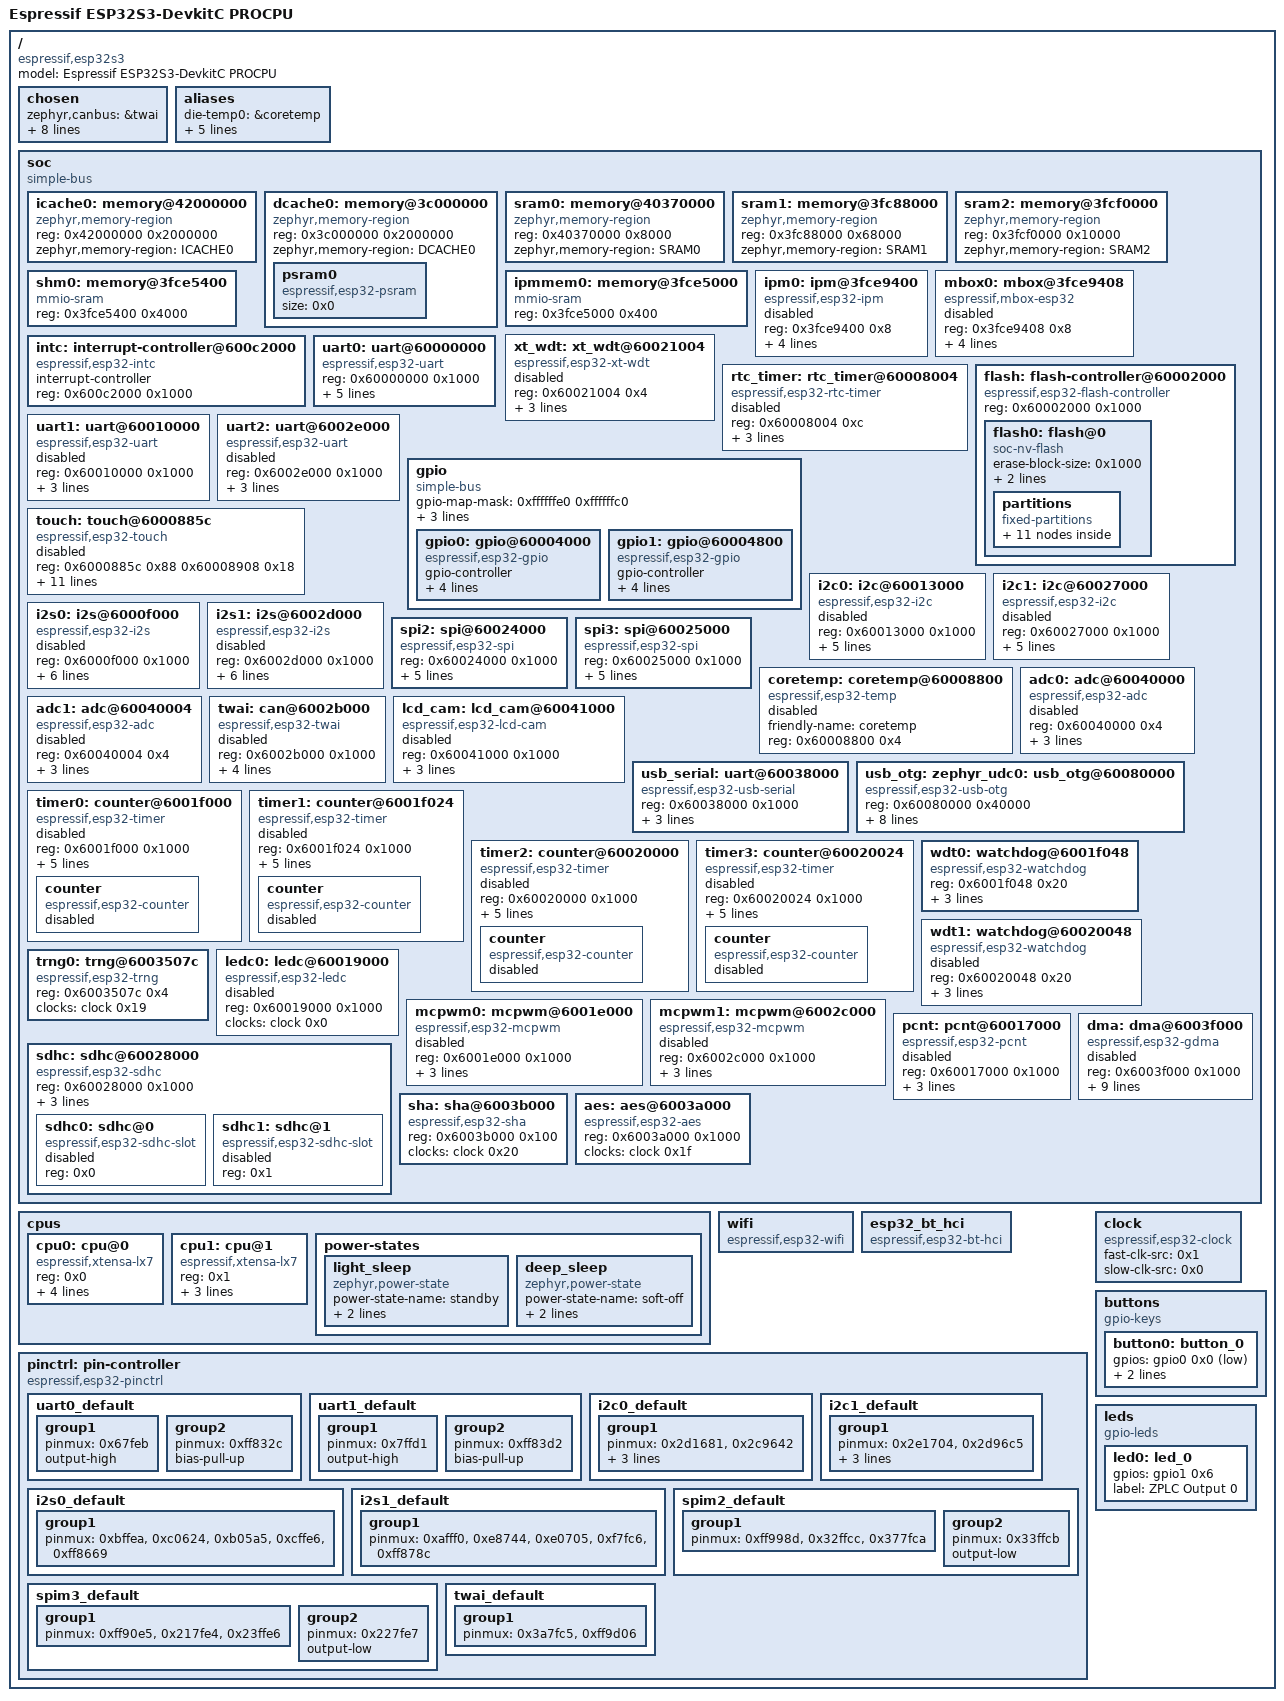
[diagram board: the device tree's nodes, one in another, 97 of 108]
/dts-v1/;

/* node '/' defined in zephyr/dts/common/skeleton.dtsi:9 */
/ {
	#address-cells = < 0x1 >;                   /* in zephyr/dts/common/skeleton.dtsi:10 */
	#size-cells = < 0x1 >;                      /* in zephyr/dts/common/skeleton.dtsi:11 */
	model = "Espressif ESP32S3-DevkitC PROCPU"; /* in zephyr/boards/espressif/esp32s3_devkitc/esp32s3_devkitc_procpu.dts:15 */
	compatible = "espressif,esp32s3";           /* in zephyr/boards/espressif/esp32s3_devkitc/esp32s3_devkitc_procpu.dts:16 */

	/* node '/chosen' defined in zephyr/dts/common/skeleton.dtsi:13 */
	chosen {
		zephyr,canbus = &twai;                    /* in zephyr/dts/xtensa/espressif/esp32s3/esp32s3_common.dtsi:22 */
		zephyr,entropy = &trng0;                  /* in zephyr/dts/xtensa/espressif/esp32s3/esp32s3_common.dtsi:23 */
		zephyr,flash-controller = &flash;         /* in zephyr/dts/xtensa/espressif/esp32s3/esp32s3_common.dtsi:24 */
		zephyr,sram = &sram1;                     /* in zephyr/boards/espressif/esp32s3_devkitc/esp32s3_devkitc_procpu.dts:24 */
		zephyr,flash = &flash0;                   /* in zephyr/boards/espressif/esp32s3_devkitc/esp32s3_devkitc_procpu.dts:27 */
		zephyr,code-partition = &slot0_partition; /* in zephyr/boards/espressif/esp32s3_devkitc/esp32s3_devkitc_procpu.dts:28 */
		zephyr,bt-hci = &esp32_bt_hci;            /* in zephyr/boards/espressif/esp32s3_devkitc/esp32s3_devkitc_procpu.dts:29 */
		zephyr,console = &usb_serial;             /* in ../Documents/Repos/ZPLC/firmware/app/boards/esp32s3_devkitc_esp32s3_procpu.overlay:27 */
		zephyr,shell-uart = &usb_serial;          /* in ../Documents/Repos/ZPLC/firmware/app/boards/esp32s3_devkitc_esp32s3_procpu.overlay:28 */
	};

	/* node '/aliases' defined in zephyr/dts/common/skeleton.dtsi:15 */
	aliases {
		die-temp0 = &coretemp; /* in zephyr/dts/xtensa/espressif/esp32s3/esp32s3_common.dtsi:18 */
		i2c-0 = &i2c0;         /* in zephyr/boards/espressif/esp32s3_devkitc/esp32s3_devkitc_procpu.dts:19 */
		watchdog0 = &wdt0;     /* in zephyr/boards/espressif/esp32s3_devkitc/esp32s3_devkitc_procpu.dts:20 */
		uart-0 = &uart0;       /* in zephyr/boards/espressif/esp32s3_devkitc/esp32s3_devkitc_procpu.dts:33 */
		sw0 = &button0;        /* in zephyr/boards/espressif/esp32s3_devkitc/esp32s3_devkitc_procpu.dts:34 */
		led0 = &led0;          /* in ../Documents/Repos/ZPLC/firmware/app/boards/esp32s3_devkitc_esp32s3_procpu.overlay:42 */
	};

	/* node '/soc' defined in zephyr/dts/xtensa/xtensa.dtsi:10 */
	soc {
		#address-cells = < 0x1 >;  /* in zephyr/dts/xtensa/espressif/esp32s3/esp32s3_common.dtsi:91 */
		#size-cells = < 0x1 >;     /* in zephyr/dts/xtensa/espressif/esp32s3/esp32s3_common.dtsi:92 */
		compatible = "simple-bus"; /* in zephyr/dts/xtensa/espressif/esp32s3/esp32s3_common.dtsi:93 */
		ranges;                    /* in zephyr/dts/xtensa/espressif/esp32s3/esp32s3_common.dtsi:94 */

		/* node '/soc/memory@42000000' defined in zephyr/dts/xtensa/espressif/esp32s3/esp32s3_common.dtsi:96 */
		icache0: memory@42000000 {
			compatible = "zephyr,memory-region"; /* in zephyr/dts/xtensa/espressif/esp32s3/esp32s3_common.dtsi:97 */
			reg = < 0x42000000 0x2000000 >;      /* in zephyr/dts/xtensa/espressif/esp32s3/esp32s3_common.dtsi:98 */
			zephyr,memory-region = "ICACHE0";    /* in zephyr/dts/xtensa/espressif/esp32s3/esp32s3_common.dtsi:99 */
		};

		/* node '/soc/memory@3c000000' defined in zephyr/dts/xtensa/espressif/esp32s3/esp32s3_common.dtsi:102 */
		dcache0: memory@3c000000 {
			compatible = "zephyr,memory-region"; /* in zephyr/dts/xtensa/espressif/esp32s3/esp32s3_common.dtsi:103 */
			reg = < 0x3c000000 0x2000000 >;      /* in zephyr/dts/xtensa/espressif/esp32s3/esp32s3_common.dtsi:104 */
			zephyr,memory-region = "DCACHE0";    /* in zephyr/dts/xtensa/espressif/esp32s3/esp32s3_common.dtsi:105 */

			/* node '/soc/memory@3c000000/psram0' defined in zephyr/dts/xtensa/espressif/esp32s3/esp32s3_common.dtsi:107 */
			psram0: psram0 {
				compatible = "espressif,esp32-psram"; /* in zephyr/dts/xtensa/espressif/esp32s3/esp32s3_common.dtsi:108 */
				size = < 0x0 >;                       /* in zephyr/dts/xtensa/espressif/esp32s3/esp32s3_common.dtsi:109 */
			};
		};

		/* node '/soc/memory@40370000' defined in zephyr/dts/xtensa/espressif/esp32s3/esp32s3_common.dtsi:113 */
		sram0: memory@40370000 {
			compatible = "zephyr,memory-region",
			             "mmio-sram";            /* in zephyr/dts/xtensa/espressif/esp32s3/esp32s3_common.dtsi:114 */
			reg = < 0x40370000 0x8000 >;         /* in zephyr/dts/xtensa/espressif/esp32s3/esp32s3_common.dtsi:115 */
			zephyr,memory-region = "SRAM0";      /* in zephyr/dts/xtensa/espressif/esp32s3/esp32s3_common.dtsi:116 */
		};

		/* node '/soc/memory@3fc88000' defined in zephyr/dts/xtensa/espressif/esp32s3/esp32s3_common.dtsi:119 */
		sram1: memory@3fc88000 {
			compatible = "zephyr,memory-region",
			             "mmio-sram";            /* in zephyr/dts/xtensa/espressif/esp32s3/esp32s3_common.dtsi:120 */
			reg = < 0x3fc88000 0x68000 >;        /* in zephyr/dts/xtensa/espressif/esp32s3/esp32s3_common.dtsi:121 */
			zephyr,memory-region = "SRAM1";      /* in zephyr/dts/xtensa/espressif/esp32s3/esp32s3_common.dtsi:122 */
		};

		/* node '/soc/memory@3fcf0000' defined in zephyr/dts/xtensa/espressif/esp32s3/esp32s3_common.dtsi:125 */
		sram2: memory@3fcf0000 {
			compatible = "zephyr,memory-region",
			             "mmio-sram";            /* in zephyr/dts/xtensa/espressif/esp32s3/esp32s3_common.dtsi:126 */
			reg = < 0x3fcf0000 0x10000 >;        /* in zephyr/dts/xtensa/espressif/esp32s3/esp32s3_common.dtsi:127 */
			zephyr,memory-region = "SRAM2";      /* in zephyr/dts/xtensa/espressif/esp32s3/esp32s3_common.dtsi:128 */
		};

		/* node '/soc/memory@3fce5000' defined in zephyr/dts/xtensa/espressif/esp32s3/esp32s3_common.dtsi:131 */
		ipmmem0: memory@3fce5000 {
			compatible = "mmio-sram";   /* in zephyr/dts/xtensa/espressif/esp32s3/esp32s3_common.dtsi:132 */
			reg = < 0x3fce5000 0x400 >; /* in zephyr/dts/xtensa/espressif/esp32s3/esp32s3_common.dtsi:133 */
			phandle = < 0x1 >;          /* in zephyr/dts/xtensa/espressif/esp32s3/esp32s3_common.dtsi:145 */
		};

		/* node '/soc/memory@3fce5400' defined in zephyr/dts/xtensa/espressif/esp32s3/esp32s3_common.dtsi:136 */
		shm0: memory@3fce5400 {
			compatible = "mmio-sram";    /* in zephyr/dts/xtensa/espressif/esp32s3/esp32s3_common.dtsi:137 */
			reg = < 0x3fce5400 0x4000 >; /* in zephyr/dts/xtensa/espressif/esp32s3/esp32s3_common.dtsi:138 */
		};

		/* node '/soc/ipm@3fce9400' defined in zephyr/dts/xtensa/espressif/esp32s3/esp32s3_common.dtsi:141 */
		ipm0: ipm@3fce9400 {
			compatible = "espressif,esp32-ipm"; /* in zephyr/dts/xtensa/espressif/esp32s3/esp32s3_common.dtsi:142 */
			reg = < 0x3fce9400 0x8 >;           /* in zephyr/dts/xtensa/espressif/esp32s3/esp32s3_common.dtsi:143 */
			status = "disabled";                /* in zephyr/dts/xtensa/espressif/esp32s3/esp32s3_common.dtsi:144 */
			shared-memory = < &ipmmem0 >;       /* in zephyr/dts/xtensa/espressif/esp32s3/esp32s3_common.dtsi:145 */
			shared-memory-size = < 0x400 >;     /* in zephyr/dts/xtensa/espressif/esp32s3/esp32s3_common.dtsi:146 */
			interrupts = < 0x4f 0x0 0x0 >,
			             < 0x50 0x0 0x0 >;      /* in zephyr/dts/xtensa/espressif/esp32s3/esp32s3_common.dtsi:147 */
			interrupt-parent = < &intc >;       /* in zephyr/dts/xtensa/espressif/esp32s3/esp32s3_common.dtsi:149 */
		};

		/* node '/soc/mbox@3fce9408' defined in zephyr/dts/xtensa/espressif/esp32s3/esp32s3_common.dtsi:152 */
		mbox0: mbox@3fce9408 {
			compatible = "espressif,mbox-esp32"; /* in zephyr/dts/xtensa/espressif/esp32s3/esp32s3_common.dtsi:153 */
			reg = < 0x3fce9408 0x8 >;            /* in zephyr/dts/xtensa/espressif/esp32s3/esp32s3_common.dtsi:154 */
			status = "disabled";                 /* in zephyr/dts/xtensa/espressif/esp32s3/esp32s3_common.dtsi:155 */
			shared-memory = < &ipmmem0 >;        /* in zephyr/dts/xtensa/espressif/esp32s3/esp32s3_common.dtsi:156 */
			shared-memory-size = < 0x400 >;      /* in zephyr/dts/xtensa/espressif/esp32s3/esp32s3_common.dtsi:157 */
			interrupts = < 0x4f 0x0 0x0 >,
			             < 0x50 0x0 0x0 >;       /* in zephyr/dts/xtensa/espressif/esp32s3/esp32s3_common.dtsi:158 */
			interrupt-parent = < &intc >;        /* in zephyr/dts/xtensa/espressif/esp32s3/esp32s3_common.dtsi:160 */
			#mbox-cells = < 0x1 >;               /* in zephyr/dts/xtensa/espressif/esp32s3/esp32s3_common.dtsi:161 */
		};

		/* node '/soc/interrupt-controller@600c2000' defined in zephyr/dts/xtensa/espressif/esp32s3/esp32s3_common.dtsi:164 */
		intc: interrupt-controller@600c2000 {
			#interrupt-cells = < 0x3 >;          /* in zephyr/dts/xtensa/espressif/esp32s3/esp32s3_common.dtsi:165 */
			#address-cells = < 0x0 >;            /* in zephyr/dts/xtensa/espressif/esp32s3/esp32s3_common.dtsi:166 */
			compatible = "espressif,esp32-intc"; /* in zephyr/dts/xtensa/espressif/esp32s3/esp32s3_common.dtsi:167 */
			interrupt-controller;                /* in zephyr/dts/xtensa/espressif/esp32s3/esp32s3_common.dtsi:168 */
			reg = < 0x600c2000 0x1000 >;         /* in zephyr/dts/xtensa/espressif/esp32s3/esp32s3_common.dtsi:169 */
			status = "okay";                     /* in zephyr/dts/xtensa/espressif/esp32s3/esp32s3_common.dtsi:170 */
			phandle = < 0x2 >;                   /* in zephyr/dts/xtensa/espressif/esp32s3/esp32s3_common.dtsi:149 */
		};

		/* node '/soc/xt_wdt@60021004' defined in zephyr/dts/xtensa/espressif/esp32s3/esp32s3_common.dtsi:173 */
		xt_wdt: xt_wdt@60021004 {
			compatible = "espressif,esp32-xt-wdt"; /* in zephyr/dts/xtensa/espressif/esp32s3/esp32s3_common.dtsi:174 */
			reg = < 0x60021004 0x4 >;              /* in zephyr/dts/xtensa/espressif/esp32s3/esp32s3_common.dtsi:175 */
			clocks = < &clock 0x28 >;              /* in zephyr/dts/xtensa/espressif/esp32s3/esp32s3_common.dtsi:176 */
			interrupts = < 0x27 0x0 0x0 >;         /* in zephyr/dts/xtensa/espressif/esp32s3/esp32s3_common.dtsi:177 */
			interrupt-parent = < &intc >;          /* in zephyr/dts/xtensa/espressif/esp32s3/esp32s3_common.dtsi:178 */
			status = "disabled";                   /* in zephyr/dts/xtensa/espressif/esp32s3/esp32s3_common.dtsi:179 */
		};

		/* node '/soc/rtc_timer@60008004' defined in zephyr/dts/xtensa/espressif/esp32s3/esp32s3_common.dtsi:182 */
		rtc_timer: rtc_timer@60008004 {
			reg = < 0x60008004 0xc >;                 /* in zephyr/dts/xtensa/espressif/esp32s3/esp32s3_common.dtsi:183 */
			compatible = "espressif,esp32-rtc-timer"; /* in zephyr/dts/xtensa/espressif/esp32s3/esp32s3_common.dtsi:184 */
			clocks = < &clock 0x28 >;                 /* in zephyr/dts/xtensa/espressif/esp32s3/esp32s3_common.dtsi:185 */
			interrupts = < 0x27 0x0 0x0 >;            /* in zephyr/dts/xtensa/espressif/esp32s3/esp32s3_common.dtsi:186 */
			interrupt-parent = < &intc >;             /* in zephyr/dts/xtensa/espressif/esp32s3/esp32s3_common.dtsi:187 */
			status = "disabled";                      /* in zephyr/dts/xtensa/espressif/esp32s3/esp32s3_common.dtsi:188 */
		};

		/* node '/soc/flash-controller@60002000' defined in zephyr/dts/xtensa/espressif/esp32s3/esp32s3_common.dtsi:191 */
		flash: flash-controller@60002000 {
			compatible = "espressif,esp32-flash-controller"; /* in zephyr/dts/xtensa/espressif/esp32s3/esp32s3_common.dtsi:192 */
			reg = < 0x60002000 0x1000 >;                     /* in zephyr/dts/xtensa/espressif/esp32s3/esp32s3_common.dtsi:193 */
			#address-cells = < 0x1 >;                        /* in zephyr/dts/xtensa/espressif/esp32s3/esp32s3_common.dtsi:194 */
			#size-cells = < 0x1 >;                           /* in zephyr/dts/xtensa/espressif/esp32s3/esp32s3_common.dtsi:195 */

			/* node '/soc/flash-controller@60002000/flash@0' defined in zephyr/dts/xtensa/espressif/esp32s3/esp32s3_common.dtsi:197 */
			flash0: flash@0 {
				compatible = "soc-nv-flash";   /* in zephyr/dts/xtensa/espressif/esp32s3/esp32s3_common.dtsi:198 */
				erase-block-size = < 0x1000 >; /* in zephyr/dts/xtensa/espressif/esp32s3/esp32s3_common.dtsi:199 */
				write-block-size = < 0x4 >;    /* in zephyr/dts/xtensa/espressif/esp32s3/esp32s3_common.dtsi:200 */
				reg = < 0x0 0x800000 >;        /* in zephyr/dts/xtensa/espressif/esp32s3/esp32s3_wroom_n8.dtsi:11 */

				/* node '/soc/flash-controller@60002000/flash@0/partitions' defined in zephyr/dts/vendor/espressif/partitions_0x0_amp_4M.dtsi:8 */
				partitions {
					compatible = "fixed-partitions"; /* in zephyr/dts/vendor/espressif/partitions_0x0_amp_4M.dtsi:9 */
					#address-cells = < 0x1 >;        /* in zephyr/dts/vendor/espressif/partitions_0x0_amp_4M.dtsi:10 */
					#size-cells = < 0x1 >;           /* in zephyr/dts/vendor/espressif/partitions_0x0_amp_4M.dtsi:11 */

					/* node '/soc/flash-controller@60002000/flash@0/partitions/partition@0' defined in zephyr/dts/vendor/espressif/partitions_0x0_amp_4M.dtsi:13 */
					boot_partition: partition@0 {
						label = "mcuboot";     /* in zephyr/dts/vendor/espressif/partitions_0x0_amp_4M.dtsi:14 */
						reg = < 0x0 0x10000 >; /* in zephyr/dts/vendor/espressif/partitions_0x0_amp_4M.dtsi:15 */
					};

					/* node '/soc/flash-controller@60002000/flash@0/partitions/partition@10000' defined in zephyr/dts/vendor/espressif/partitions_0x0_amp_4M.dtsi:18 */
					sys_partition: partition@10000 {
						label = "sys";             /* in zephyr/dts/vendor/espressif/partitions_0x0_amp_4M.dtsi:19 */
						reg = < 0x10000 0x10000 >; /* in zephyr/dts/vendor/espressif/partitions_0x0_amp_4M.dtsi:20 */
					};

					/* node '/soc/flash-controller@60002000/flash@0/partitions/partition@20000' defined in zephyr/dts/vendor/espressif/partitions_0x0_amp_4M.dtsi:23 */
					slot0_partition: partition@20000 {
						label = "image-0";          /* in zephyr/dts/vendor/espressif/partitions_0x0_amp_4M.dtsi:24 */
						reg = < 0x20000 0x150000 >; /* in zephyr/dts/vendor/espressif/partitions_0x0_amp_4M.dtsi:25 */
					};

					/* node '/soc/flash-controller@60002000/flash@0/partitions/partition@170000' defined in zephyr/dts/vendor/espressif/partitions_0x0_amp_4M.dtsi:28 */
					slot1_partition: partition@170000 {
						label = "image-1";           /* in zephyr/dts/vendor/espressif/partitions_0x0_amp_4M.dtsi:29 */
						reg = < 0x170000 0x150000 >; /* in zephyr/dts/vendor/espressif/partitions_0x0_amp_4M.dtsi:30 */
					};

					/* node '/soc/flash-controller@60002000/flash@0/partitions/partition@2c0000' defined in zephyr/dts/vendor/espressif/partitions_0x0_amp_4M.dtsi:33 */
					slot0_appcpu_partition: partition@2c0000 {
						label = "image-0-appcpu";   /* in zephyr/dts/vendor/espressif/partitions_0x0_amp_4M.dtsi:34 */
						reg = < 0x2c0000 0x70000 >; /* in zephyr/dts/vendor/espressif/partitions_0x0_amp_4M.dtsi:35 */
					};

					/* node '/soc/flash-controller@60002000/flash@0/partitions/partition@330000' defined in zephyr/dts/vendor/espressif/partitions_0x0_amp_4M.dtsi:38 */
					slot1_appcpu_partition: partition@330000 {
						label = "image-1-appcpu";   /* in zephyr/dts/vendor/espressif/partitions_0x0_amp_4M.dtsi:39 */
						reg = < 0x330000 0x70000 >; /* in zephyr/dts/vendor/espressif/partitions_0x0_amp_4M.dtsi:40 */
					};

					/* node '/soc/flash-controller@60002000/flash@0/partitions/partition@3a0000' defined in zephyr/dts/vendor/espressif/partitions_0x0_amp_4M.dtsi:43 */
					slot0_lpcore_partition: partition@3a0000 {
						label = "image-0-lpcore";  /* in zephyr/dts/vendor/espressif/partitions_0x0_amp_4M.dtsi:44 */
						reg = < 0x3a0000 0x8000 >; /* in zephyr/dts/vendor/espressif/partitions_0x0_amp_4M.dtsi:45 */
					};

					/* node '/soc/flash-controller@60002000/flash@0/partitions/partition@3a8000' defined in zephyr/dts/vendor/espressif/partitions_0x0_amp_4M.dtsi:48 */
					slot1_lpcore_partition: partition@3a8000 {
						label = "image-1-lpcore";  /* in zephyr/dts/vendor/espressif/partitions_0x0_amp_4M.dtsi:49 */
						reg = < 0x3a8000 0x8000 >; /* in zephyr/dts/vendor/espressif/partitions_0x0_amp_4M.dtsi:50 */
					};

					/* node '/soc/flash-controller@60002000/flash@0/partitions/partition@3b0000' defined in zephyr/dts/vendor/espressif/partitions_0x0_amp_4M.dtsi:53 */
					storage_partition: partition@3b0000 {
						label = "storage";          /* in zephyr/dts/vendor/espressif/partitions_0x0_amp_4M.dtsi:54 */
						reg = < 0x3b0000 0x30000 >; /* in zephyr/dts/vendor/espressif/partitions_0x0_amp_4M.dtsi:55 */
					};

					/* node '/soc/flash-controller@60002000/flash@0/partitions/partition@3e0000' defined in zephyr/dts/vendor/espressif/partitions_0x0_amp_4M.dtsi:58 */
					scratch_partition: partition@3e0000 {
						label = "image-scratch";    /* in zephyr/dts/vendor/espressif/partitions_0x0_amp_4M.dtsi:59 */
						reg = < 0x3e0000 0x1f000 >; /* in zephyr/dts/vendor/espressif/partitions_0x0_amp_4M.dtsi:60 */
					};

					/* node '/soc/flash-controller@60002000/flash@0/partitions/partition@3ff000' defined in zephyr/dts/vendor/espressif/partitions_0x0_amp_4M.dtsi:63 */
					coredump_partition: partition@3ff000 {
						label = "coredump";        /* in zephyr/dts/vendor/espressif/partitions_0x0_amp_4M.dtsi:64 */
						reg = < 0x3ff000 0x1000 >; /* in zephyr/dts/vendor/espressif/partitions_0x0_amp_4M.dtsi:65 */
					};
				};
			};
		};

		/* node '/soc/uart@60000000' defined in zephyr/dts/xtensa/espressif/esp32s3/esp32s3_common.dtsi:205 */
		uart0: uart@60000000 {
			compatible = "espressif,esp32-uart"; /* in zephyr/dts/xtensa/espressif/esp32s3/esp32s3_common.dtsi:206 */
			reg = < 0x60000000 0x1000 >;         /* in zephyr/dts/xtensa/espressif/esp32s3/esp32s3_common.dtsi:207 */
			interrupts = < 0x1b 0x0 0x0 >;       /* in zephyr/dts/xtensa/espressif/esp32s3/esp32s3_common.dtsi:208 */
			interrupt-parent = < &intc >;        /* in zephyr/dts/xtensa/espressif/esp32s3/esp32s3_common.dtsi:209 */
			clocks = < &clock 0x1 >;             /* in zephyr/dts/xtensa/espressif/esp32s3/esp32s3_common.dtsi:210 */
			status = "okay";                     /* in zephyr/boards/espressif/esp32s3_devkitc/esp32s3_devkitc_procpu.dts:53 */
			current-speed = < 0x1c200 >;         /* in zephyr/boards/espressif/esp32s3_devkitc/esp32s3_devkitc_procpu.dts:54 */
			pinctrl-0 = < &uart0_default >;      /* in zephyr/boards/espressif/esp32s3_devkitc/esp32s3_devkitc_procpu.dts:55 */
			pinctrl-names = "default";           /* in zephyr/boards/espressif/esp32s3_devkitc/esp32s3_devkitc_procpu.dts:56 */
		};

		/* node '/soc/uart@60010000' defined in zephyr/dts/xtensa/espressif/esp32s3/esp32s3_common.dtsi:214 */
		uart1: uart@60010000 {
			compatible = "espressif,esp32-uart"; /* in zephyr/dts/xtensa/espressif/esp32s3/esp32s3_common.dtsi:215 */
			reg = < 0x60010000 0x1000 >;         /* in zephyr/dts/xtensa/espressif/esp32s3/esp32s3_common.dtsi:216 */
			interrupts = < 0x1c 0x0 0x0 >;       /* in zephyr/dts/xtensa/espressif/esp32s3/esp32s3_common.dtsi:217 */
			interrupt-parent = < &intc >;        /* in zephyr/dts/xtensa/espressif/esp32s3/esp32s3_common.dtsi:218 */
			clocks = < &clock 0x2 >;             /* in zephyr/dts/xtensa/espressif/esp32s3/esp32s3_common.dtsi:219 */
			status = "disabled";                 /* in zephyr/dts/xtensa/espressif/esp32s3/esp32s3_common.dtsi:220 */
		};

		/* node '/soc/uart@6002e000' defined in zephyr/dts/xtensa/espressif/esp32s3/esp32s3_common.dtsi:223 */
		uart2: uart@6002e000 {
			compatible = "espressif,esp32-uart"; /* in zephyr/dts/xtensa/espressif/esp32s3/esp32s3_common.dtsi:224 */
			reg = < 0x6002e000 0x1000 >;         /* in zephyr/dts/xtensa/espressif/esp32s3/esp32s3_common.dtsi:225 */
			interrupts = < 0x1d 0x0 0x0 >;       /* in zephyr/dts/xtensa/espressif/esp32s3/esp32s3_common.dtsi:226 */
			interrupt-parent = < &intc >;        /* in zephyr/dts/xtensa/espressif/esp32s3/esp32s3_common.dtsi:227 */
			clocks = < &clock 0x3 >;             /* in zephyr/dts/xtensa/espressif/esp32s3/esp32s3_common.dtsi:228 */
			status = "disabled";                 /* in zephyr/dts/xtensa/espressif/esp32s3/esp32s3_common.dtsi:229 */
		};

		/* node '/soc/gpio' defined in zephyr/dts/xtensa/espressif/esp32s3/esp32s3_common.dtsi:232 */
		gpio: gpio {
			compatible = "simple-bus";                                     /* in zephyr/dts/xtensa/espressif/esp32s3/esp32s3_common.dtsi:233 */
			gpio-map-mask = < 0xffffffe0 0xffffffc0 >;                     /* in zephyr/dts/xtensa/espressif/esp32s3/esp32s3_common.dtsi:234 */
			gpio-map-pass-thru = < 0x1f 0x3f >;                            /* in zephyr/dts/xtensa/espressif/esp32s3/esp32s3_common.dtsi:235 */
			gpio-map = < 0x0 0x0 &gpio0 0x0 0x0 0x20 0x0 &gpio1 0x0 0x0 >; /* in zephyr/dts/xtensa/espressif/esp32s3/esp32s3_common.dtsi:236 */
			#gpio-cells = < 0x2 >;                                         /* in zephyr/dts/xtensa/espressif/esp32s3/esp32s3_common.dtsi:238 */
			#address-cells = < 0x1 >;                                      /* in zephyr/dts/xtensa/espressif/esp32s3/esp32s3_common.dtsi:239 */
			#size-cells = < 0x1 >;                                         /* in zephyr/dts/xtensa/espressif/esp32s3/esp32s3_common.dtsi:240 */
			ranges;                                                        /* in zephyr/dts/xtensa/espressif/esp32s3/esp32s3_common.dtsi:241 */

			/* node '/soc/gpio/gpio@60004000' defined in zephyr/dts/xtensa/espressif/esp32s3/esp32s3_common.dtsi:243 */
			gpio0: gpio@60004000 {
				compatible = "espressif,esp32-gpio"; /* in zephyr/dts/xtensa/espressif/esp32s3/esp32s3_common.dtsi:244 */
				gpio-controller;                     /* in zephyr/dts/xtensa/espressif/esp32s3/esp32s3_common.dtsi:245 */
				#gpio-cells = < 0x2 >;               /* in zephyr/dts/xtensa/espressif/esp32s3/esp32s3_common.dtsi:246 */
				reg = < 0x60004000 0x800 >;          /* in zephyr/dts/xtensa/espressif/esp32s3/esp32s3_common.dtsi:247 */
				interrupts = < 0x10 0x0 0x0 >;       /* in zephyr/dts/xtensa/espressif/esp32s3/esp32s3_common.dtsi:248 */
				interrupt-parent = < &intc >;        /* in zephyr/dts/xtensa/espressif/esp32s3/esp32s3_common.dtsi:249 */
				ngpios = < 0x20 >;                   /* in zephyr/dts/xtensa/espressif/esp32s3/esp32s3_common.dtsi:255 */
				status = "okay";                     /* in zephyr/boards/espressif/esp32s3_devkitc/esp32s3_devkitc_procpu.dts:60 */
				phandle = < 0x5 >;                   /* in zephyr/dts/xtensa/espressif/esp32s3/esp32s3_common.dtsi:236 */
			};

			/* node '/soc/gpio/gpio@60004800' defined in zephyr/dts/xtensa/espressif/esp32s3/esp32s3_common.dtsi:258 */
			gpio1: gpio@60004800 {
				compatible = "espressif,esp32-gpio"; /* in zephyr/dts/xtensa/espressif/esp32s3/esp32s3_common.dtsi:259 */
				gpio-controller;                     /* in zephyr/dts/xtensa/espressif/esp32s3/esp32s3_common.dtsi:260 */
				#gpio-cells = < 0x2 >;               /* in zephyr/dts/xtensa/espressif/esp32s3/esp32s3_common.dtsi:261 */
				reg = < 0x60004800 0x800 >;          /* in zephyr/dts/xtensa/espressif/esp32s3/esp32s3_common.dtsi:262 */
				interrupts = < 0x10 0x0 0x0 >;       /* in zephyr/dts/xtensa/espressif/esp32s3/esp32s3_common.dtsi:263 */
				interrupt-parent = < &intc >;        /* in zephyr/dts/xtensa/espressif/esp32s3/esp32s3_common.dtsi:264 */
				ngpios = < 0x16 >;                   /* in zephyr/dts/xtensa/espressif/esp32s3/esp32s3_common.dtsi:265 */
				status = "okay";                     /* in zephyr/boards/espressif/esp32s3_devkitc/esp32s3_devkitc_procpu.dts:64 */
				phandle = < 0x6 >;                   /* in zephyr/dts/xtensa/espressif/esp32s3/esp32s3_common.dtsi:236 */
			};
		};

		/* node '/soc/touch@6000885c' defined in zephyr/dts/xtensa/espressif/esp32s3/esp32s3_common.dtsi:269 */
		touch: touch@6000885c {
			compatible = "espressif,esp32-touch";      /* in zephyr/dts/xtensa/espressif/esp32s3/esp32s3_common.dtsi:270 */
			reg = < 0x6000885c 0x88 0x60008908 0x18 >; /* in zephyr/dts/xtensa/espressif/esp32s3/esp32s3_common.dtsi:271 */
			interrupts = < 0x27 0x0 0x0 >;             /* in zephyr/dts/xtensa/espressif/esp32s3/esp32s3_common.dtsi:272 */
			interrupt-parent = < &intc >;              /* in zephyr/dts/xtensa/espressif/esp32s3/esp32s3_common.dtsi:273 */
			status = "disabled";                       /* in zephyr/dts/xtensa/espressif/esp32s3/esp32s3_common.dtsi:274 */
			debounce-interval-ms = < 0x1e >;           /* in zephyr/boards/espressif/esp32s3_devkitc/esp32s3_devkitc_procpu.dts:68 */
			href-microvolt = < 0x2932e0 >;             /* in zephyr/boards/espressif/esp32s3_devkitc/esp32s3_devkitc_procpu.dts:69 */
			lref-microvolt = < 0x7a120 >;              /* in zephyr/boards/espressif/esp32s3_devkitc/esp32s3_devkitc_procpu.dts:70 */
			href-atten-microvolt = < 0xf4240 >;        /* in zephyr/boards/espressif/esp32s3_devkitc/esp32s3_devkitc_procpu.dts:71 */
			filter-mode = < 0x2 >;                     /* in zephyr/boards/espressif/esp32s3_devkitc/esp32s3_devkitc_procpu.dts:72 */
			filter-debounce-cnt = < 0x1 >;             /* in zephyr/boards/espressif/esp32s3_devkitc/esp32s3_devkitc_procpu.dts:73 */
			filter-noise-thr = < 0x0 >;                /* in zephyr/boards/espressif/esp32s3_devkitc/esp32s3_devkitc_procpu.dts:74 */
			filter-jitter-step = < 0x4 >;              /* in zephyr/boards/espressif/esp32s3_devkitc/esp32s3_devkitc_procpu.dts:75 */
			filter-smooth-level = < 0x1 >;             /* in zephyr/boards/espressif/esp32s3_devkitc/esp32s3_devkitc_procpu.dts:76 */
		};

		/* node '/soc/i2c@60013000' defined in zephyr/dts/xtensa/espressif/esp32s3/esp32s3_common.dtsi:277 */
		i2c0: i2c@60013000 {
			compatible = "espressif,esp32-i2c"; /* in zephyr/dts/xtensa/espressif/esp32s3/esp32s3_common.dtsi:278 */
			#address-cells = < 0x1 >;           /* in zephyr/dts/xtensa/espressif/esp32s3/esp32s3_common.dtsi:279 */
			#size-cells = < 0x0 >;              /* in zephyr/dts/xtensa/espressif/esp32s3/esp32s3_common.dtsi:280 */
			reg = < 0x60013000 0x1000 >;        /* in zephyr/dts/xtensa/espressif/esp32s3/esp32s3_common.dtsi:281 */
			interrupts = < 0x2a 0x0 0x0 >;      /* in zephyr/dts/xtensa/espressif/esp32s3/esp32s3_common.dtsi:282 */
			interrupt-parent = < &intc >;       /* in zephyr/dts/xtensa/espressif/esp32s3/esp32s3_common.dtsi:283 */
			clocks = < &clock 0x5 >;            /* in zephyr/dts/xtensa/espressif/esp32s3/esp32s3_common.dtsi:284 */
			status = "disabled";                /* in zephyr/dts/xtensa/espressif/esp32s3/esp32s3_common.dtsi:285 */
			clock-frequency = < 0x186a0 >;      /* in zephyr/boards/espressif/esp32s3_devkitc/esp32s3_devkitc_procpu.dts:80 */
			pinctrl-0 = < &i2c0_default >;      /* in zephyr/boards/espressif/esp32s3_devkitc/esp32s3_devkitc_procpu.dts:81 */
			pinctrl-names = "default";          /* in zephyr/boards/espressif/esp32s3_devkitc/esp32s3_devkitc_procpu.dts:82 */
		};

		/* node '/soc/i2c@60027000' defined in zephyr/dts/xtensa/espressif/esp32s3/esp32s3_common.dtsi:288 */
		i2c1: i2c@60027000 {
			compatible = "espressif,esp32-i2c"; /* in zephyr/dts/xtensa/espressif/esp32s3/esp32s3_common.dtsi:289 */
			#address-cells = < 0x1 >;           /* in zephyr/dts/xtensa/espressif/esp32s3/esp32s3_common.dtsi:290 */
			#size-cells = < 0x0 >;              /* in zephyr/dts/xtensa/espressif/esp32s3/esp32s3_common.dtsi:291 */
			reg = < 0x60027000 0x1000 >;        /* in zephyr/dts/xtensa/espressif/esp32s3/esp32s3_common.dtsi:292 */
			interrupts = < 0x2b 0x0 0x0 >;      /* in zephyr/dts/xtensa/espressif/esp32s3/esp32s3_common.dtsi:293 */
			interrupt-parent = < &intc >;       /* in zephyr/dts/xtensa/espressif/esp32s3/esp32s3_common.dtsi:294 */
			clocks = < &clock 0x6 >;            /* in zephyr/dts/xtensa/espressif/esp32s3/esp32s3_common.dtsi:295 */
			status = "disabled";                /* in zephyr/dts/xtensa/espressif/esp32s3/esp32s3_common.dtsi:296 */
			clock-frequency = < 0x186a0 >;      /* in zephyr/boards/espressif/esp32s3_devkitc/esp32s3_devkitc_procpu.dts:86 */
			pinctrl-0 = < &i2c1_default >;      /* in zephyr/boards/espressif/esp32s3_devkitc/esp32s3_devkitc_procpu.dts:87 */
			pinctrl-names = "default";          /* in zephyr/boards/espressif/esp32s3_devkitc/esp32s3_devkitc_procpu.dts:88 */
		};

		/* node '/soc/i2s@6000f000' defined in zephyr/dts/xtensa/espressif/esp32s3/esp32s3_common.dtsi:299 */
		i2s0: i2s@6000f000 {
			compatible = "espressif,esp32-i2s"; /* in zephyr/dts/xtensa/espressif/esp32s3/esp32s3_common.dtsi:300 */
			#address-cells = < 0x1 >;           /* in zephyr/dts/xtensa/espressif/esp32s3/esp32s3_common.dtsi:301 */
			#size-cells = < 0x0 >;              /* in zephyr/dts/xtensa/espressif/esp32s3/esp32s3_common.dtsi:302 */
			reg = < 0x6000f000 0x1000 >;        /* in zephyr/dts/xtensa/espressif/esp32s3/esp32s3_common.dtsi:303 */
			interrupts = < 0x19 0x0 0x0 >;      /* in zephyr/dts/xtensa/espressif/esp32s3/esp32s3_common.dtsi:304 */
			interrupt-parent = < &intc >;       /* in zephyr/dts/xtensa/espressif/esp32s3/esp32s3_common.dtsi:305 */
			clocks = < &clock 0x7 >;            /* in zephyr/dts/xtensa/espressif/esp32s3/esp32s3_common.dtsi:306 */
			dmas = < &dma 0x2 >,
			       < &dma 0x3 >;                /* in zephyr/dts/xtensa/espressif/esp32s3/esp32s3_common.dtsi:307 */
			dma-names = "rx",
			            "tx";                   /* in zephyr/dts/xtensa/espressif/esp32s3/esp32s3_common.dtsi:308 */
			unit = < 0x0 >;                     /* in zephyr/dts/xtensa/espressif/esp32s3/esp32s3_common.dtsi:309 */
			status = "disabled";                /* in zephyr/dts/xtensa/espressif/esp32s3/esp32s3_common.dtsi:310 */
			pinctrl-0 = < &i2s0_default >;      /* in zephyr/boards/espressif/esp32s3_devkitc/esp32s3_devkitc_procpu.dts:92 */
			pinctrl-names = "default";          /* in zephyr/boards/espressif/esp32s3_devkitc/esp32s3_devkitc_procpu.dts:93 */
		};

		/* node '/soc/i2s@6002d000' defined in zephyr/dts/xtensa/espressif/esp32s3/esp32s3_common.dtsi:313 */
		i2s1: i2s@6002d000 {
			compatible = "espressif,esp32-i2s"; /* in zephyr/dts/xtensa/espressif/esp32s3/esp32s3_common.dtsi:314 */
			#address-cells = < 0x1 >;           /* in zephyr/dts/xtensa/espressif/esp32s3/esp32s3_common.dtsi:315 */
			#size-cells = < 0x0 >;              /* in zephyr/dts/xtensa/espressif/esp32s3/esp32s3_common.dtsi:316 */
			reg = < 0x6002d000 0x1000 >;        /* in zephyr/dts/xtensa/espressif/esp32s3/esp32s3_common.dtsi:317 */
			interrupts = < 0x1a 0x0 0x0 >;      /* in zephyr/dts/xtensa/espressif/esp32s3/esp32s3_common.dtsi:318 */
			interrupt-parent = < &intc >;       /* in zephyr/dts/xtensa/espressif/esp32s3/esp32s3_common.dtsi:319 */
			clocks = < &clock 0x8 >;            /* in zephyr/dts/xtensa/espressif/esp32s3/esp32s3_common.dtsi:320 */
			dmas = < &dma 0x4 >,
			       < &dma 0x5 >;                /* in zephyr/dts/xtensa/espressif/esp32s3/esp32s3_common.dtsi:321 */
			dma-names = "rx",
			            "tx";                   /* in zephyr/dts/xtensa/espressif/esp32s3/esp32s3_common.dtsi:322 */
			unit = < 0x1 >;                     /* in zephyr/dts/xtensa/espressif/esp32s3/esp32s3_common.dtsi:323 */
			status = "disabled";                /* in zephyr/dts/xtensa/espressif/esp32s3/esp32s3_common.dtsi:324 */
			pinctrl-0 = < &i2s1_default >;      /* in zephyr/boards/espressif/esp32s3_devkitc/esp32s3_devkitc_procpu.dts:97 */
			pinctrl-names = "default";          /* in zephyr/boards/espressif/esp32s3_devkitc/esp32s3_devkitc_procpu.dts:98 */
		};

		/* node '/soc/spi@60024000' defined in zephyr/dts/xtensa/espressif/esp32s3/esp32s3_common.dtsi:327 */
		spi2: spi@60024000 {
			compatible = "espressif,esp32-spi"; /* in zephyr/dts/xtensa/espressif/esp32s3/esp32s3_common.dtsi:328 */
			reg = < 0x60024000 0x1000 >;        /* in zephyr/dts/xtensa/espressif/esp32s3/esp32s3_common.dtsi:329 */
			interrupts = < 0x15 0x0 0x0 >;      /* in zephyr/dts/xtensa/espressif/esp32s3/esp32s3_common.dtsi:330 */
			interrupt-parent = < &intc >;       /* in zephyr/dts/xtensa/espressif/esp32s3/esp32s3_common.dtsi:331 */
			clocks = < &clock 0x15 >;           /* in zephyr/dts/xtensa/espressif/esp32s3/esp32s3_common.dtsi:332 */
			dma-host = < 0x0 >;                 /* in zephyr/dts/xtensa/espressif/esp32s3/esp32s3_common.dtsi:333 */
			#address-cells = < 0x1 >;           /* in zephyr/boards/espressif/esp32s3_devkitc/esp32s3_devkitc_procpu.dts:102 */
			#size-cells = < 0x0 >;              /* in zephyr/boards/espressif/esp32s3_devkitc/esp32s3_devkitc_procpu.dts:103 */
			status = "okay";                    /* in zephyr/boards/espressif/esp32s3_devkitc/esp32s3_devkitc_procpu.dts:104 */
			pinctrl-0 = < &spim2_default >;     /* in zephyr/boards/espressif/esp32s3_devkitc/esp32s3_devkitc_procpu.dts:105 */
			pinctrl-names = "default";          /* in zephyr/boards/espressif/esp32s3_devkitc/esp32s3_devkitc_procpu.dts:106 */
		};

		/* node '/soc/spi@60025000' defined in zephyr/dts/xtensa/espressif/esp32s3/esp32s3_common.dtsi:337 */
		spi3: spi@60025000 {
			compatible = "espressif,esp32-spi"; /* in zephyr/dts/xtensa/espressif/esp32s3/esp32s3_common.dtsi:338 */
			reg = < 0x60025000 0x1000 >;        /* in zephyr/dts/xtensa/espressif/esp32s3/esp32s3_common.dtsi:339 */
			interrupts = < 0x16 0x0 0x0 >;      /* in zephyr/dts/xtensa/espressif/esp32s3/esp32s3_common.dtsi:340 */
			interrupt-parent = < &intc >;       /* in zephyr/dts/xtensa/espressif/esp32s3/esp32s3_common.dtsi:341 */
			clocks = < &clock 0x16 >;           /* in zephyr/dts/xtensa/espressif/esp32s3/esp32s3_common.dtsi:342 */
			dma-host = < 0x1 >;                 /* in zephyr/dts/xtensa/espressif/esp32s3/esp32s3_common.dtsi:343 */
			#address-cells = < 0x1 >;           /* in zephyr/boards/espressif/esp32s3_devkitc/esp32s3_devkitc_procpu.dts:110 */
			#size-cells = < 0x0 >;              /* in zephyr/boards/espressif/esp32s3_devkitc/esp32s3_devkitc_procpu.dts:111 */
			status = "okay";                    /* in zephyr/boards/espressif/esp32s3_devkitc/esp32s3_devkitc_procpu.dts:112 */
			pinctrl-0 = < &spim3_default >;     /* in zephyr/boards/espressif/esp32s3_devkitc/esp32s3_devkitc_procpu.dts:113 */
			pinctrl-names = "default";          /* in zephyr/boards/espressif/esp32s3_devkitc/esp32s3_devkitc_procpu.dts:114 */
		};

		/* node '/soc/coretemp@60008800' defined in zephyr/dts/xtensa/espressif/esp32s3/esp32s3_common.dtsi:347 */
		coretemp: coretemp@60008800 {
			compatible = "espressif,esp32-temp"; /* in zephyr/dts/xtensa/espressif/esp32s3/esp32s3_common.dtsi:348 */
			friendly-name = "coretemp";          /* in zephyr/dts/xtensa/espressif/esp32s3/esp32s3_common.dtsi:349 */
			reg = < 0x60008800 0x4 >;            /* in zephyr/dts/xtensa/espressif/esp32s3/esp32s3_common.dtsi:350 */
			status = "disabled";                 /* in zephyr/dts/xtensa/espressif/esp32s3/esp32s3_common.dtsi:351 */
		};

		/* node '/soc/adc@60040000' defined in zephyr/dts/xtensa/espressif/esp32s3/esp32s3_common.dtsi:354 */
		adc0: adc@60040000 {
			compatible = "espressif,esp32-adc"; /* in zephyr/dts/xtensa/espressif/esp32s3/esp32s3_common.dtsi:355 */
			reg = < 0x60040000 0x4 >;           /* in zephyr/dts/xtensa/espressif/esp32s3/esp32s3_common.dtsi:356 */
			clocks = < &clock 0x27 >;           /* in zephyr/dts/xtensa/espressif/esp32s3/esp32s3_common.dtsi:357 */
			unit = < 0x1 >;                     /* in zephyr/dts/xtensa/espressif/esp32s3/esp32s3_common.dtsi:358 */
			channel-count = < 0xa >;            /* in zephyr/dts/xtensa/espressif/esp32s3/esp32s3_common.dtsi:359 */
			#io-channel-cells = < 0x1 >;        /* in zephyr/dts/xtensa/espressif/esp32s3/esp32s3_common.dtsi:360 */
			status = "disabled";                /* in zephyr/dts/xtensa/espressif/esp32s3/esp32s3_common.dtsi:361 */
		};

		/* node '/soc/adc@60040004' defined in zephyr/dts/xtensa/espressif/esp32s3/esp32s3_common.dtsi:364 */
		adc1: adc@60040004 {
			compatible = "espressif,esp32-adc"; /* in zephyr/dts/xtensa/espressif/esp32s3/esp32s3_common.dtsi:365 */
			reg = < 0x60040004 0x4 >;           /* in zephyr/dts/xtensa/espressif/esp32s3/esp32s3_common.dtsi:366 */
			clocks = < &clock 0x27 >;           /* in zephyr/dts/xtensa/espressif/esp32s3/esp32s3_common.dtsi:367 */
			unit = < 0x2 >;                     /* in zephyr/dts/xtensa/espressif/esp32s3/esp32s3_common.dtsi:368 */
			channel-count = < 0xa >;            /* in zephyr/dts/xtensa/espressif/esp32s3/esp32s3_common.dtsi:369 */
			#io-channel-cells = < 0x1 >;        /* in zephyr/dts/xtensa/espressif/esp32s3/esp32s3_common.dtsi:370 */
			status = "disabled";                /* in zephyr/dts/xtensa/espressif/esp32s3/esp32s3_common.dtsi:371 */
		};

		/* node '/soc/can@6002b000' defined in zephyr/dts/xtensa/espressif/esp32s3/esp32s3_common.dtsi:374 */
		twai: can@6002b000 {
			compatible = "espressif,esp32-twai"; /* in zephyr/dts/xtensa/espressif/esp32s3/esp32s3_common.dtsi:375 */
			reg = < 0x6002b000 0x1000 >;         /* in zephyr/dts/xtensa/espressif/esp32s3/esp32s3_common.dtsi:376 */
			interrupts = < 0x25 0x0 0x0 >;       /* in zephyr/dts/xtensa/espressif/esp32s3/esp32s3_common.dtsi:377 */
			interrupt-parent = < &intc >;        /* in zephyr/dts/xtensa/espressif/esp32s3/esp32s3_common.dtsi:378 */
			clocks = < &clock 0x18 >;            /* in zephyr/dts/xtensa/espressif/esp32s3/esp32s3_common.dtsi:379 */
			status = "disabled";                 /* in zephyr/dts/xtensa/espressif/esp32s3/esp32s3_common.dtsi:380 */
			pinctrl-0 = < &twai_default >;       /* in zephyr/boards/espressif/esp32s3_devkitc/esp32s3_devkitc_procpu.dts:118 */
			pinctrl-names = "default";           /* in zephyr/boards/espressif/esp32s3_devkitc/esp32s3_devkitc_procpu.dts:119 */
		};

		/* node '/soc/lcd_cam@60041000' defined in zephyr/dts/xtensa/espressif/esp32s3/esp32s3_common.dtsi:383 */
		lcd_cam: lcd_cam@60041000 {
			compatible = "espressif,esp32-lcd-cam"; /* in zephyr/dts/xtensa/espressif/esp32s3/esp32s3_common.dtsi:384 */
			reg = < 0x60041000 0x1000 >;            /* in zephyr/dts/xtensa/espressif/esp32s3/esp32s3_common.dtsi:385 */
			clocks = < &clock 0x9 >;                /* in zephyr/dts/xtensa/espressif/esp32s3/esp32s3_common.dtsi:386 */
			interrupts = < 0x18 0x0 0x0 >;          /* in zephyr/dts/xtensa/espressif/esp32s3/esp32s3_common.dtsi:387 */
			interrupt-parent = < &intc >;           /* in zephyr/dts/xtensa/espressif/esp32s3/esp32s3_common.dtsi:388 */
			status = "disabled";                    /* in zephyr/dts/xtensa/espressif/esp32s3/esp32s3_common.dtsi:389 */
		};

		/* node '/soc/uart@60038000' defined in zephyr/dts/xtensa/espressif/esp32s3/esp32s3_common.dtsi:392 */
		usb_serial: uart@60038000 {
			compatible = "espressif,esp32-usb-serial"; /* in zephyr/dts/xtensa/espressif/esp32s3/esp32s3_common.dtsi:393 */
			reg = < 0x60038000 0x1000 >;               /* in zephyr/dts/xtensa/espressif/esp32s3/esp32s3_common.dtsi:394 */
			interrupts = < 0x60 0x0 0x0 >;             /* in zephyr/dts/xtensa/espressif/esp32s3/esp32s3_common.dtsi:396 */
			interrupt-parent = < &intc >;              /* in zephyr/dts/xtensa/espressif/esp32s3/esp32s3_common.dtsi:397 */
			clocks = < &clock 0x4 >;                   /* in zephyr/dts/xtensa/espressif/esp32s3/esp32s3_common.dtsi:398 */
			status = "okay";                           /* in ../Documents/Repos/ZPLC/firmware/app/boards/esp32s3_devkitc_esp32s3_procpu.overlay:48 */
		};

		/* node '/soc/usb_otg@60080000' defined in zephyr/dts/xtensa/espressif/esp32s3/esp32s3_common.dtsi:401 */
		usb_otg: zephyr_udc0: usb_otg@60080000 {
			compatible = "espressif,esp32-usb-otg",
			             "snps,dwc2";               /* in zephyr/dts/xtensa/espressif/esp32s3/esp32s3_common.dtsi:402 */
			reg = < 0x60080000 0x40000 >;           /* in zephyr/dts/xtensa/espressif/esp32s3/esp32s3_common.dtsi:403 */
			interrupts = < 0x26 0x0 0x0 >;          /* in zephyr/dts/xtensa/espressif/esp32s3/esp32s3_common.dtsi:405 */
			interrupt-parent = < &intc >;           /* in zephyr/dts/xtensa/espressif/esp32s3/esp32s3_common.dtsi:406 */
			clocks = < &clock 0x4 >;                /* in zephyr/dts/xtensa/espressif/esp32s3/esp32s3_common.dtsi:407 */
			num-out-eps = < 0x6 >;                  /* in zephyr/dts/xtensa/espressif/esp32s3/esp32s3_common.dtsi:408 */
			num-in-eps = < 0x6 >;                   /* in zephyr/dts/xtensa/espressif/esp32s3/esp32s3_common.dtsi:409 */
			ghwcfg1 = < 0x0 >;                      /* in zephyr/dts/xtensa/espressif/esp32s3/esp32s3_common.dtsi:410 */
			ghwcfg2 = < 0x224dd930 >;               /* in zephyr/dts/xtensa/espressif/esp32s3/esp32s3_common.dtsi:411 */
			ghwcfg4 = < 0xd3f0a030 >;               /* in zephyr/dts/xtensa/espressif/esp32s3/esp32s3_common.dtsi:412 */
			status = "okay";                        /* in zephyr/boards/espressif/esp32s3_devkitc/esp32s3_devkitc_procpu.dts:155 */
		};

		/* node '/soc/counter@6001f000' defined in zephyr/dts/xtensa/espressif/esp32s3/esp32s3_common.dtsi:415 */
		timer0: counter@6001f000 {
			compatible = "espressif,esp32-timer"; /* in zephyr/dts/xtensa/espressif/esp32s3/esp32s3_common.dtsi:416 */
			reg = < 0x6001f000 0x1000 >;          /* in zephyr/dts/xtensa/espressif/esp32s3/esp32s3_common.dtsi:417 */
			clocks = < &clock 0xa >;              /* in zephyr/dts/xtensa/espressif/esp32s3/esp32s3_common.dtsi:418 */
			group = < 0x0 >;                      /* in zephyr/dts/xtensa/espressif/esp32s3/esp32s3_common.dtsi:419 */
			index = < 0x0 >;                      /* in zephyr/dts/xtensa/espressif/esp32s3/esp32s3_common.dtsi:420 */
			interrupts = < 0x32 0x0 0x0 >;        /* in zephyr/dts/xtensa/espressif/esp32s3/esp32s3_common.dtsi:421 */
			interrupt-parent = < &intc >;         /* in zephyr/dts/xtensa/espressif/esp32s3/esp32s3_common.dtsi:422 */
			status = "disabled";                  /* in zephyr/boards/espressif/esp32s3_devkitc/esp32s3_devkitc_procpu.dts:123 */

			/* node '/soc/counter@6001f000/counter' defined in zephyr/dts/xtensa/espressif/esp32s3/esp32s3_common.dtsi:425 */
			counter {
				compatible = "espressif,esp32-counter"; /* in zephyr/dts/xtensa/espressif/esp32s3/esp32s3_common.dtsi:426 */
				status = "disabled";                    /* in zephyr/dts/xtensa/espressif/esp32s3/esp32s3_common.dtsi:427 */
			};
		};

		/* node '/soc/counter@6001f024' defined in zephyr/dts/xtensa/espressif/esp32s3/esp32s3_common.dtsi:431 */
		timer1: counter@6001f024 {
			compatible = "espressif,esp32-timer"; /* in zephyr/dts/xtensa/espressif/esp32s3/esp32s3_common.dtsi:432 */
			reg = < 0x6001f024 0x1000 >;          /* in zephyr/dts/xtensa/espressif/esp32s3/esp32s3_common.dtsi:433 */
			clocks = < &clock 0xa >;              /* in zephyr/dts/xtensa/espressif/esp32s3/esp32s3_common.dtsi:434 */
			group = < 0x0 >;                      /* in zephyr/dts/xtensa/espressif/esp32s3/esp32s3_common.dtsi:435 */
			index = < 0x1 >;                      /* in zephyr/dts/xtensa/espressif/esp32s3/esp32s3_common.dtsi:436 */
			interrupts = < 0x33 0x0 0x0 >;        /* in zephyr/dts/xtensa/espressif/esp32s3/esp32s3_common.dtsi:437 */
			interrupt-parent = < &intc >;         /* in zephyr/dts/xtensa/espressif/esp32s3/esp32s3_common.dtsi:438 */
			status = "disabled";                  /* in zephyr/boards/espressif/esp32s3_devkitc/esp32s3_devkitc_procpu.dts:127 */

			/* node '/soc/counter@6001f024/counter' defined in zephyr/dts/xtensa/espressif/esp32s3/esp32s3_common.dtsi:441 */
			counter {
				compatible = "espressif,esp32-counter"; /* in zephyr/dts/xtensa/espressif/esp32s3/esp32s3_common.dtsi:442 */
				status = "disabled";                    /* in zephyr/dts/xtensa/espressif/esp32s3/esp32s3_common.dtsi:443 */
			};
		};

		/* node '/soc/counter@60020000' defined in zephyr/dts/xtensa/espressif/esp32s3/esp32s3_common.dtsi:447 */
		timer2: counter@60020000 {
			compatible = "espressif,esp32-timer"; /* in zephyr/dts/xtensa/espressif/esp32s3/esp32s3_common.dtsi:448 */
			reg = < 0x60020000 0x1000 >;          /* in zephyr/dts/xtensa/espressif/esp32s3/esp32s3_common.dtsi:449 */
			clocks = < &clock 0xb >;              /* in zephyr/dts/xtensa/espressif/esp32s3/esp32s3_common.dtsi:450 */
			group = < 0x1 >;                      /* in zephyr/dts/xtensa/espressif/esp32s3/esp32s3_common.dtsi:451 */
			index = < 0x0 >;                      /* in zephyr/dts/xtensa/espressif/esp32s3/esp32s3_common.dtsi:452 */
			interrupts = < 0x35 0x0 0x0 >;        /* in zephyr/dts/xtensa/espressif/esp32s3/esp32s3_common.dtsi:453 */
			interrupt-parent = < &intc >;         /* in zephyr/dts/xtensa/espressif/esp32s3/esp32s3_common.dtsi:454 */
			status = "disabled";                  /* in zephyr/boards/espressif/esp32s3_devkitc/esp32s3_devkitc_procpu.dts:131 */

			/* node '/soc/counter@60020000/counter' defined in zephyr/dts/xtensa/espressif/esp32s3/esp32s3_common.dtsi:457 */
			counter {
				compatible = "espressif,esp32-counter"; /* in zephyr/dts/xtensa/espressif/esp32s3/esp32s3_common.dtsi:458 */
				status = "disabled";                    /* in zephyr/dts/xtensa/espressif/esp32s3/esp32s3_common.dtsi:459 */
			};
		};

		/* node '/soc/counter@60020024' defined in zephyr/dts/xtensa/espressif/esp32s3/esp32s3_common.dtsi:463 */
		timer3: counter@60020024 {
			compatible = "espressif,esp32-timer"; /* in zephyr/dts/xtensa/espressif/esp32s3/esp32s3_common.dtsi:464 */
			reg = < 0x60020024 0x1000 >;          /* in zephyr/dts/xtensa/espressif/esp32s3/esp32s3_common.dtsi:465 */
			clocks = < &clock 0xb >;              /* in zephyr/dts/xtensa/espressif/esp32s3/esp32s3_common.dtsi:466 */
			group = < 0x1 >;                      /* in zephyr/dts/xtensa/espressif/esp32s3/esp32s3_common.dtsi:467 */
			index = < 0x1 >;                      /* in zephyr/dts/xtensa/espressif/esp32s3/esp32s3_common.dtsi:468 */
			interrupts = < 0x36 0x0 0x0 >;        /* in zephyr/dts/xtensa/espressif/esp32s3/esp32s3_common.dtsi:469 */
			interrupt-parent = < &intc >;         /* in zephyr/dts/xtensa/espressif/esp32s3/esp32s3_common.dtsi:470 */
			status = "disabled";                  /* in zephyr/boards/espressif/esp32s3_devkitc/esp32s3_devkitc_procpu.dts:135 */

			/* node '/soc/counter@60020024/counter' defined in zephyr/dts/xtensa/espressif/esp32s3/esp32s3_common.dtsi:472 */
			counter {
				compatible = "espressif,esp32-counter"; /* in zephyr/dts/xtensa/espressif/esp32s3/esp32s3_common.dtsi:473 */
				status = "disabled";                    /* in zephyr/dts/xtensa/espressif/esp32s3/esp32s3_common.dtsi:474 */
			};
		};

		/* node '/soc/watchdog@6001f048' defined in zephyr/dts/xtensa/espressif/esp32s3/esp32s3_common.dtsi:478 */
		wdt0: watchdog@6001f048 {
			compatible = "espressif,esp32-watchdog"; /* in zephyr/dts/xtensa/espressif/esp32s3/esp32s3_common.dtsi:479 */
			reg = < 0x6001f048 0x20 >;               /* in zephyr/dts/xtensa/espressif/esp32s3/esp32s3_common.dtsi:480 */
			interrupts = < 0x34 0x0 0x0 >;           /* in zephyr/dts/xtensa/espressif/esp32s3/esp32s3_common.dtsi:481 */
			interrupt-parent = < &intc >;            /* in zephyr/dts/xtensa/espressif/esp32s3/esp32s3_common.dtsi:482 */
			clocks = < &clock 0xa >;                 /* in zephyr/dts/xtensa/espressif/esp32s3/esp32s3_common.dtsi:483 */
			status = "okay";                         /* in zephyr/boards/espressif/esp32s3_devkitc/esp32s3_devkitc_procpu.dts:139 */
		};

		/* node '/soc/watchdog@60020048' defined in zephyr/dts/xtensa/espressif/esp32s3/esp32s3_common.dtsi:487 */
		wdt1: watchdog@60020048 {
			compatible = "espressif,esp32-watchdog"; /* in zephyr/dts/xtensa/espressif/esp32s3/esp32s3_common.dtsi:488 */
			reg = < 0x60020048 0x20 >;               /* in zephyr/dts/xtensa/espressif/esp32s3/esp32s3_common.dtsi:489 */
			interrupts = < 0x37 0x0 0x0 >;           /* in zephyr/dts/xtensa/espressif/esp32s3/esp32s3_common.dtsi:490 */
			interrupt-parent = < &intc >;            /* in zephyr/dts/xtensa/espressif/esp32s3/esp32s3_common.dtsi:491 */
			clocks = < &clock 0xb >;                 /* in zephyr/dts/xtensa/espressif/esp32s3/esp32s3_common.dtsi:492 */
			status = "disabled";                     /* in zephyr/dts/xtensa/espressif/esp32s3/esp32s3_common.dtsi:493 */
		};

		/* node '/soc/trng@6003507c' defined in zephyr/dts/xtensa/espressif/esp32s3/esp32s3_common.dtsi:496 */
		trng0: trng@6003507c {
			compatible = "espressif,esp32-trng"; /* in zephyr/dts/xtensa/espressif/esp32s3/esp32s3_common.dtsi:497 */
			reg = < 0x6003507c 0x4 >;            /* in zephyr/dts/xtensa/espressif/esp32s3/esp32s3_common.dtsi:498 */
			clocks = < &clock 0x19 >;            /* in zephyr/dts/xtensa/espressif/esp32s3/esp32s3_common.dtsi:499 */
			status = "okay";                     /* in zephyr/boards/espressif/esp32s3_devkitc/esp32s3_devkitc_procpu.dts:143 */
		};

		/* node '/soc/ledc@60019000' defined in zephyr/dts/xtensa/espressif/esp32s3/esp32s3_common.dtsi:503 */
		ledc0: ledc@60019000 {
			compatible = "espressif,esp32-ledc"; /* in zephyr/dts/xtensa/espressif/esp32s3/esp32s3_common.dtsi:504 */
			#pwm-cells = < 0x3 >;                /* in zephyr/dts/xtensa/espressif/esp32s3/esp32s3_common.dtsi:505 */
			reg = < 0x60019000 0x1000 >;         /* in zephyr/dts/xtensa/espressif/esp32s3/esp32s3_common.dtsi:506 */
			clocks = < &clock 0x0 >;             /* in zephyr/dts/xtensa/espressif/esp32s3/esp32s3_common.dtsi:507 */
			status = "disabled";                 /* in zephyr/dts/xtensa/espressif/esp32s3/esp32s3_common.dtsi:508 */
		};

		/* node '/soc/mcpwm@6001e000' defined in zephyr/dts/xtensa/espressif/esp32s3/esp32s3_common.dtsi:511 */
		mcpwm0: mcpwm@6001e000 {
			compatible = "espressif,esp32-mcpwm"; /* in zephyr/dts/xtensa/espressif/esp32s3/esp32s3_common.dtsi:512 */
			reg = < 0x6001e000 0x1000 >;          /* in zephyr/dts/xtensa/espressif/esp32s3/esp32s3_common.dtsi:513 */
			interrupts = < 0x1f 0x0 0x0 >;        /* in zephyr/dts/xtensa/espressif/esp32s3/esp32s3_common.dtsi:514 */
			interrupt-parent = < &intc >;         /* in zephyr/dts/xtensa/espressif/esp32s3/esp32s3_common.dtsi:515 */
			clocks = < &clock 0xc >;              /* in zephyr/dts/xtensa/espressif/esp32s3/esp32s3_common.dtsi:516 */
			#pwm-cells = < 0x3 >;                 /* in zephyr/dts/xtensa/espressif/esp32s3/esp32s3_common.dtsi:517 */
			status = "disabled";                  /* in zephyr/dts/xtensa/espressif/esp32s3/esp32s3_common.dtsi:518 */
		};

		/* node '/soc/mcpwm@6002c000' defined in zephyr/dts/xtensa/espressif/esp32s3/esp32s3_common.dtsi:521 */
		mcpwm1: mcpwm@6002c000 {
			compatible = "espressif,esp32-mcpwm"; /* in zephyr/dts/xtensa/espressif/esp32s3/esp32s3_common.dtsi:522 */
			reg = < 0x6002c000 0x1000 >;          /* in zephyr/dts/xtensa/espressif/esp32s3/esp32s3_common.dtsi:523 */
			interrupts = < 0x20 0x0 0x0 >;        /* in zephyr/dts/xtensa/espressif/esp32s3/esp32s3_common.dtsi:524 */
			interrupt-parent = < &intc >;         /* in zephyr/dts/xtensa/espressif/esp32s3/esp32s3_common.dtsi:525 */
			clocks = < &clock 0xd >;              /* in zephyr/dts/xtensa/espressif/esp32s3/esp32s3_common.dtsi:526 */
			#pwm-cells = < 0x3 >;                 /* in zephyr/dts/xtensa/espressif/esp32s3/esp32s3_common.dtsi:527 */
			status = "disabled";                  /* in zephyr/dts/xtensa/espressif/esp32s3/esp32s3_common.dtsi:528 */
		};

		/* node '/soc/pcnt@60017000' defined in zephyr/dts/xtensa/espressif/esp32s3/esp32s3_common.dtsi:531 */
		pcnt: pcnt@60017000 {
			compatible = "espressif,esp32-pcnt"; /* in zephyr/dts/xtensa/espressif/esp32s3/esp32s3_common.dtsi:532 */
			reg = < 0x60017000 0x1000 >;         /* in zephyr/dts/xtensa/espressif/esp32s3/esp32s3_common.dtsi:533 */
			interrupts = < 0x29 0x0 0x0 >;       /* in zephyr/dts/xtensa/espressif/esp32s3/esp32s3_common.dtsi:534 */
			interrupt-parent = < &intc >;        /* in zephyr/dts/xtensa/espressif/esp32s3/esp32s3_common.dtsi:535 */
			clocks = < &clock 0x13 >;            /* in zephyr/dts/xtensa/espressif/esp32s3/esp32s3_common.dtsi:536 */
			status = "disabled";                 /* in zephyr/dts/xtensa/espressif/esp32s3/esp32s3_common.dtsi:537 */
		};

		/* node '/soc/dma@6003f000' defined in zephyr/dts/xtensa/espressif/esp32s3/esp32s3_common.dtsi:540 */
		dma: dma@6003f000 {
			compatible = "espressif,esp32-gdma"; /* in zephyr/dts/xtensa/espressif/esp32s3/esp32s3_common.dtsi:541 */
			reg = < 0x6003f000 0x1000 >;         /* in zephyr/dts/xtensa/espressif/esp32s3/esp32s3_common.dtsi:542 */
			#dma-cells = < 0x1 >;                /* in zephyr/dts/xtensa/espressif/esp32s3/esp32s3_common.dtsi:543 */
			interrupts = < 0x42 0x0 0x100 >,
			             < 0x47 0x0 0x100 >,
			             < 0x43 0x0 0x100 >,
			             < 0x48 0x0 0x100 >,
			             < 0x44 0x0 0x100 >,
			             < 0x49 0x0 0x100 >,
			             < 0x45 0x0 0x100 >,
			             < 0x4a 0x0 0x100 >,
			             < 0x46 0x0 0x100 >,
			             < 0x4b 0x0 0x100 >;     /* in zephyr/dts/xtensa/espressif/esp32s3/esp32s3_common.dtsi:544 */
			interrupt-parent = < &intc >;        /* in zephyr/dts/xtensa/espressif/esp32s3/esp32s3_common.dtsi:564 */
			clocks = < &clock 0x25 >;            /* in zephyr/dts/xtensa/espressif/esp32s3/esp32s3_common.dtsi:565 */
			dma-channels = < 0xa >;              /* in zephyr/dts/xtensa/espressif/esp32s3/esp32s3_common.dtsi:566 */
			dma-buf-addr-alignment = < 0x4 >;    /* in zephyr/dts/xtensa/espressif/esp32s3/esp32s3_common.dtsi:567 */
			status = "disabled";                 /* in zephyr/dts/xtensa/espressif/esp32s3/esp32s3_common.dtsi:568 */
			phandle = < 0x9 >;                   /* in zephyr/dts/xtensa/espressif/esp32s3/esp32s3_common.dtsi:307 */
		};

		/* node '/soc/sdhc@60028000' defined in zephyr/dts/xtensa/espressif/esp32s3/esp32s3_common.dtsi:571 */
		sdhc: sdhc@60028000 {
			compatible = "espressif,esp32-sdhc"; /* in zephyr/dts/xtensa/espressif/esp32s3/esp32s3_common.dtsi:572 */
			reg = < 0x60028000 0x1000 >;         /* in zephyr/dts/xtensa/espressif/esp32s3/esp32s3_common.dtsi:573 */
			interrupts = < 0x1e 0x0 0x0 >;       /* in zephyr/dts/xtensa/espressif/esp32s3/esp32s3_common.dtsi:574 */
			interrupt-parent = < &intc >;        /* in zephyr/dts/xtensa/espressif/esp32s3/esp32s3_common.dtsi:575 */
			clocks = < &clock 0x17 >;            /* in zephyr/dts/xtensa/espressif/esp32s3/esp32s3_common.dtsi:576 */
			#address-cells = < 0x1 >;            /* in zephyr/dts/xtensa/espressif/esp32s3/esp32s3_common.dtsi:577 */
			#size-cells = < 0x0 >;               /* in zephyr/dts/xtensa/espressif/esp32s3/esp32s3_common.dtsi:578 */

			/* node '/soc/sdhc@60028000/sdhc@0' defined in zephyr/dts/xtensa/espressif/esp32s3/esp32s3_common.dtsi:580 */
			sdhc0: sdhc@0 {
				compatible = "espressif,esp32-sdhc-slot"; /* in zephyr/dts/xtensa/espressif/esp32s3/esp32s3_common.dtsi:581 */
				reg = < 0x0 >;                            /* in zephyr/dts/xtensa/espressif/esp32s3/esp32s3_common.dtsi:582 */
				status = "disabled";                      /* in zephyr/dts/xtensa/espressif/esp32s3/esp32s3_common.dtsi:583 */
			};

			/* node '/soc/sdhc@60028000/sdhc@1' defined in zephyr/dts/xtensa/espressif/esp32s3/esp32s3_common.dtsi:586 */
			sdhc1: sdhc@1 {
				compatible = "espressif,esp32-sdhc-slot"; /* in zephyr/dts/xtensa/espressif/esp32s3/esp32s3_common.dtsi:587 */
				reg = < 0x1 >;                            /* in zephyr/dts/xtensa/espressif/esp32s3/esp32s3_common.dtsi:588 */
				status = "disabled";                      /* in zephyr/dts/xtensa/espressif/esp32s3/esp32s3_common.dtsi:589 */
			};
		};

		/* node '/soc/sha@6003b000' defined in zephyr/dts/xtensa/espressif/esp32s3/esp32s3_common.dtsi:593 */
		sha: sha@6003b000 {
			compatible = "espressif,esp32-sha"; /* in zephyr/dts/xtensa/espressif/esp32s3/esp32s3_common.dtsi:594 */
			reg = < 0x6003b000 0x100 >;         /* in zephyr/dts/xtensa/espressif/esp32s3/esp32s3_common.dtsi:595 */
			clocks = < &clock 0x20 >;           /* in zephyr/dts/xtensa/espressif/esp32s3/esp32s3_common.dtsi:596 */
			status = "okay";                    /* in zephyr/dts/xtensa/espressif/esp32s3/esp32s3_common.dtsi:597 */
		};

		/* node '/soc/aes@6003a000' defined in zephyr/dts/xtensa/espressif/esp32s3/esp32s3_common.dtsi:600 */
		aes: aes@6003a000 {
			compatible = "espressif,esp32-aes"; /* in zephyr/dts/xtensa/espressif/esp32s3/esp32s3_common.dtsi:601 */
			reg = < 0x6003a000 0x1000 >;        /* in zephyr/dts/xtensa/espressif/esp32s3/esp32s3_common.dtsi:602 */
			clocks = < &clock 0x1f >;           /* in zephyr/dts/xtensa/espressif/esp32s3/esp32s3_common.dtsi:603 */
			status = "okay";                    /* in zephyr/dts/xtensa/espressif/esp32s3/esp32s3_common.dtsi:604 */
		};
	};

	/* node '/cpus' defined in zephyr/dts/xtensa/espressif/esp32s3/esp32s3_common.dtsi:27 */
	cpus {
		#address-cells = < 0x1 >; /* in zephyr/dts/xtensa/espressif/esp32s3/esp32s3_common.dtsi:28 */
		#size-cells = < 0x0 >;    /* in zephyr/dts/xtensa/espressif/esp32s3/esp32s3_common.dtsi:29 */

		/* node '/cpus/cpu@0' defined in zephyr/dts/xtensa/espressif/esp32s3/esp32s3_common.dtsi:31 */
		cpu0: cpu@0 {
			device_type = "cpu";                             /* in zephyr/dts/xtensa/espressif/esp32s3/esp32s3_common.dtsi:32 */
			compatible = "espressif,xtensa-lx7";             /* in zephyr/dts/xtensa/espressif/esp32s3/esp32s3_common.dtsi:33 */
			reg = < 0x0 >;                                   /* in zephyr/dts/xtensa/espressif/esp32s3/esp32s3_common.dtsi:34 */
			cpu-power-states = < &light_sleep &deep_sleep >; /* in zephyr/dts/xtensa/espressif/esp32s3/esp32s3_common.dtsi:35 */
			clock-source = < 0x1 >;                          /* in zephyr/dts/xtensa/espressif/esp32s3/esp32s3_common.dtsi:36 */
			clock-frequency = < 0xe4e1c00 >;                 /* in zephyr/dts/xtensa/espressif/esp32s3/esp32s3_common.dtsi:37 */
			xtal-freq = < 0x2625a00 >;                       /* in zephyr/dts/xtensa/espressif/esp32s3/esp32s3_common.dtsi:38 */
		};

		/* node '/cpus/cpu@1' defined in zephyr/dts/xtensa/espressif/esp32s3/esp32s3_common.dtsi:41 */
		cpu1: cpu@1 {
			device_type = "cpu";                 /* in zephyr/dts/xtensa/espressif/esp32s3/esp32s3_common.dtsi:42 */
			compatible = "espressif,xtensa-lx7"; /* in zephyr/dts/xtensa/espressif/esp32s3/esp32s3_common.dtsi:43 */
			reg = < 0x1 >;                       /* in zephyr/dts/xtensa/espressif/esp32s3/esp32s3_common.dtsi:44 */
			clock-source = < 0x1 >;              /* in zephyr/dts/xtensa/espressif/esp32s3/esp32s3_common.dtsi:45 */
			clock-frequency = < 0xe4e1c00 >;     /* in zephyr/dts/xtensa/espressif/esp32s3/esp32s3_common.dtsi:46 */
			xtal-freq = < 0x2625a00 >;           /* in zephyr/dts/xtensa/espressif/esp32s3/esp32s3_common.dtsi:47 */
		};

		/* node '/cpus/power-states' defined in zephyr/dts/xtensa/espressif/esp32s3/esp32s3_common.dtsi:50 */
		power-states {

			/* node '/cpus/power-states/light_sleep' defined in zephyr/dts/xtensa/espressif/esp32s3/esp32s3_common.dtsi:51 */
			light_sleep: light_sleep {
				compatible = "zephyr,power-state"; /* in zephyr/dts/xtensa/espressif/esp32s3/esp32s3_common.dtsi:52 */
				power-state-name = "standby";      /* in zephyr/dts/xtensa/espressif/esp32s3/esp32s3_common.dtsi:53 */
				min-residency-us = < 0xc8 >;       /* in zephyr/dts/xtensa/espressif/esp32s3/esp32s3_common.dtsi:54 */
				exit-latency-us = < 0x85 >;        /* in zephyr/dts/xtensa/espressif/esp32s3/esp32s3_common.dtsi:55 */
				phandle = < 0xf >;                 /* in zephyr/dts/xtensa/espressif/esp32s3/esp32s3_common.dtsi:35 */
			};

			/* node '/cpus/power-states/deep_sleep' defined in zephyr/dts/xtensa/espressif/esp32s3/esp32s3_common.dtsi:58 */
			deep_sleep: deep_sleep {
				compatible = "zephyr,power-state"; /* in zephyr/dts/xtensa/espressif/esp32s3/esp32s3_common.dtsi:59 */
				power-state-name = "soft-off";     /* in zephyr/dts/xtensa/espressif/esp32s3/esp32s3_common.dtsi:60 */
				min-residency-us = < 0x7d0 >;      /* in zephyr/dts/xtensa/espressif/esp32s3/esp32s3_common.dtsi:61 */
				exit-latency-us = < 0x17e >;       /* in zephyr/dts/xtensa/espressif/esp32s3/esp32s3_common.dtsi:62 */
				phandle = < 0x10 >;                /* in zephyr/dts/xtensa/espressif/esp32s3/esp32s3_common.dtsi:35 */
			};
		};
	};

	/* node '/wifi' defined in zephyr/dts/xtensa/espressif/esp32s3/esp32s3_common.dtsi:67 */
	wifi: wifi {
		compatible = "espressif,esp32-wifi"; /* in zephyr/dts/xtensa/espressif/esp32s3/esp32s3_common.dtsi:68 */
		status = "okay";                     /* in zephyr/boards/espressif/esp32s3_devkitc/esp32s3_devkitc_procpu.dts:151 */
	};

	/* node '/esp32_bt_hci' defined in zephyr/dts/xtensa/espressif/esp32s3/esp32s3_common.dtsi:72 */
	esp32_bt_hci: esp32_bt_hci {
		compatible = "espressif,esp32-bt-hci"; /* in zephyr/dts/xtensa/espressif/esp32s3/esp32s3_common.dtsi:73 */
		status = "okay";                       /* in zephyr/boards/espressif/esp32s3_devkitc/esp32s3_devkitc_procpu.dts:147 */
	};

	/* node '/pin-controller' defined in zephyr/dts/xtensa/espressif/esp32s3/esp32s3_common.dtsi:77 */
	pinctrl: pin-controller {
		compatible = "espressif,esp32-pinctrl"; /* in zephyr/dts/xtensa/espressif/esp32s3/esp32s3_common.dtsi:78 */
		status = "okay";                        /* in zephyr/dts/xtensa/espressif/esp32s3/esp32s3_common.dtsi:79 */

		/* node '/pin-controller/uart0_default' defined in zephyr/boards/espressif/esp32s3_devkitc/esp32s3_devkitc-pinctrl.dtsi:12 */
		uart0_default: uart0_default {
			phandle = < 0x4 >; /* in zephyr/boards/espressif/esp32s3_devkitc/esp32s3_devkitc_procpu.dts:55 */

			/* node '/pin-controller/uart0_default/group1' defined in zephyr/boards/espressif/esp32s3_devkitc/esp32s3_devkitc-pinctrl.dtsi:13 */
			group1 {
				pinmux = < 0x67feb >; /* in zephyr/boards/espressif/esp32s3_devkitc/esp32s3_devkitc-pinctrl.dtsi:14 */
				output-high;          /* in zephyr/boards/espressif/esp32s3_devkitc/esp32s3_devkitc-pinctrl.dtsi:15 */
			};

			/* node '/pin-controller/uart0_default/group2' defined in zephyr/boards/espressif/esp32s3_devkitc/esp32s3_devkitc-pinctrl.dtsi:18 */
			group2 {
				pinmux = < 0xff832c >; /* in zephyr/boards/espressif/esp32s3_devkitc/esp32s3_devkitc-pinctrl.dtsi:19 */
				bias-pull-up;          /* in zephyr/boards/espressif/esp32s3_devkitc/esp32s3_devkitc-pinctrl.dtsi:20 */
			};
		};

		/* node '/pin-controller/uart1_default' defined in zephyr/boards/espressif/esp32s3_devkitc/esp32s3_devkitc-pinctrl.dtsi:24 */
		uart1_default: uart1_default {

			/* node '/pin-controller/uart1_default/group1' defined in zephyr/boards/espressif/esp32s3_devkitc/esp32s3_devkitc-pinctrl.dtsi:25 */
			group1 {
				pinmux = < 0x7ffd1 >; /* in zephyr/boards/espressif/esp32s3_devkitc/esp32s3_devkitc-pinctrl.dtsi:26 */
				output-high;          /* in zephyr/boards/espressif/esp32s3_devkitc/esp32s3_devkitc-pinctrl.dtsi:27 */
			};

			/* node '/pin-controller/uart1_default/group2' defined in zephyr/boards/espressif/esp32s3_devkitc/esp32s3_devkitc-pinctrl.dtsi:30 */
			group2 {
				pinmux = < 0xff83d2 >; /* in zephyr/boards/espressif/esp32s3_devkitc/esp32s3_devkitc-pinctrl.dtsi:31 */
				bias-pull-up;          /* in zephyr/boards/espressif/esp32s3_devkitc/esp32s3_devkitc-pinctrl.dtsi:32 */
			};
		};

		/* node '/pin-controller/i2c0_default' defined in zephyr/boards/espressif/esp32s3_devkitc/esp32s3_devkitc-pinctrl.dtsi:36 */
		i2c0_default: i2c0_default {
			phandle = < 0x7 >; /* in zephyr/boards/espressif/esp32s3_devkitc/esp32s3_devkitc_procpu.dts:81 */

			/* node '/pin-controller/i2c0_default/group1' defined in zephyr/boards/espressif/esp32s3_devkitc/esp32s3_devkitc-pinctrl.dtsi:37 */
			group1 {
				pinmux = < 0x2d1681 >,
				         < 0x2c9642 >; /* in zephyr/boards/espressif/esp32s3_devkitc/esp32s3_devkitc-pinctrl.dtsi:38 */
				bias-pull-up;          /* in zephyr/boards/espressif/esp32s3_devkitc/esp32s3_devkitc-pinctrl.dtsi:40 */
				drive-open-drain;      /* in zephyr/boards/espressif/esp32s3_devkitc/esp32s3_devkitc-pinctrl.dtsi:41 */
				output-high;           /* in zephyr/boards/espressif/esp32s3_devkitc/esp32s3_devkitc-pinctrl.dtsi:42 */
			};
		};

		/* node '/pin-controller/i2c1_default' defined in zephyr/boards/espressif/esp32s3_devkitc/esp32s3_devkitc-pinctrl.dtsi:46 */
		i2c1_default: i2c1_default {
			phandle = < 0x8 >; /* in zephyr/boards/espressif/esp32s3_devkitc/esp32s3_devkitc_procpu.dts:87 */

			/* node '/pin-controller/i2c1_default/group1' defined in zephyr/boards/espressif/esp32s3_devkitc/esp32s3_devkitc-pinctrl.dtsi:47 */
			group1 {
				pinmux = < 0x2e1704 >,
				         < 0x2d96c5 >; /* in zephyr/boards/espressif/esp32s3_devkitc/esp32s3_devkitc-pinctrl.dtsi:48 */
				bias-pull-up;          /* in zephyr/boards/espressif/esp32s3_devkitc/esp32s3_devkitc-pinctrl.dtsi:50 */
				drive-open-drain;      /* in zephyr/boards/espressif/esp32s3_devkitc/esp32s3_devkitc-pinctrl.dtsi:51 */
				output-high;           /* in zephyr/boards/espressif/esp32s3_devkitc/esp32s3_devkitc-pinctrl.dtsi:52 */
			};
		};

		/* node '/pin-controller/i2s0_default' defined in zephyr/boards/espressif/esp32s3_devkitc/esp32s3_devkitc-pinctrl.dtsi:56 */
		i2s0_default: i2s0_default {
			phandle = < 0xa >; /* in zephyr/boards/espressif/esp32s3_devkitc/esp32s3_devkitc_procpu.dts:92 */

			/* node '/pin-controller/i2s0_default/group1' defined in zephyr/boards/espressif/esp32s3_devkitc/esp32s3_devkitc-pinctrl.dtsi:57 */
			group1 {
				pinmux = < 0xbffea >,
				         < 0xc0624 >,
				         < 0xb05a5 >,
				         < 0xcffe6 >,
				         < 0xff8669 >; /* in zephyr/boards/espressif/esp32s3_devkitc/esp32s3_devkitc-pinctrl.dtsi:58 */
			};
		};

		/* node '/pin-controller/i2s1_default' defined in zephyr/boards/espressif/esp32s3_devkitc/esp32s3_devkitc-pinctrl.dtsi:66 */
		i2s1_default: i2s1_default {
			phandle = < 0xb >; /* in zephyr/boards/espressif/esp32s3_devkitc/esp32s3_devkitc_procpu.dts:97 */

			/* node '/pin-controller/i2s1_default/group1' defined in zephyr/boards/espressif/esp32s3_devkitc/esp32s3_devkitc-pinctrl.dtsi:67 */
			group1 {
				pinmux = < 0xafff0 >,
				         < 0xe8744 >,
				         < 0xe0705 >,
				         < 0xf7fc6 >,
				         < 0xff878c >; /* in zephyr/boards/espressif/esp32s3_devkitc/esp32s3_devkitc-pinctrl.dtsi:68 */
			};
		};

		/* node '/pin-controller/spim2_default' defined in zephyr/boards/espressif/esp32s3_devkitc/esp32s3_devkitc-pinctrl.dtsi:76 */
		spim2_default: spim2_default {
			phandle = < 0xc >; /* in zephyr/boards/espressif/esp32s3_devkitc/esp32s3_devkitc_procpu.dts:105 */

			/* node '/pin-controller/spim2_default/group1' defined in zephyr/boards/espressif/esp32s3_devkitc/esp32s3_devkitc-pinctrl.dtsi:77 */
			group1 {
				pinmux = < 0xff998d >,
				         < 0x32ffcc >,
				         < 0x377fca >; /* in zephyr/boards/espressif/esp32s3_devkitc/esp32s3_devkitc-pinctrl.dtsi:78 */
			};

			/* node '/pin-controller/spim2_default/group2' defined in zephyr/boards/espressif/esp32s3_devkitc/esp32s3_devkitc-pinctrl.dtsi:83 */
			group2 {
				pinmux = < 0x33ffcb >; /* in zephyr/boards/espressif/esp32s3_devkitc/esp32s3_devkitc-pinctrl.dtsi:84 */
				output-low;            /* in zephyr/boards/espressif/esp32s3_devkitc/esp32s3_devkitc-pinctrl.dtsi:85 */
			};
		};

		/* node '/pin-controller/spim3_default' defined in zephyr/boards/espressif/esp32s3_devkitc/esp32s3_devkitc-pinctrl.dtsi:89 */
		spim3_default: spim3_default {
			phandle = < 0xd >; /* in zephyr/boards/espressif/esp32s3_devkitc/esp32s3_devkitc_procpu.dts:113 */

			/* node '/pin-controller/spim3_default/group1' defined in zephyr/boards/espressif/esp32s3_devkitc/esp32s3_devkitc-pinctrl.dtsi:90 */
			group1 {
				pinmux = < 0xff90e5 >,
				         < 0x217fe4 >,
				         < 0x23ffe6 >; /* in zephyr/boards/espressif/esp32s3_devkitc/esp32s3_devkitc-pinctrl.dtsi:91 */
			};

			/* node '/pin-controller/spim3_default/group2' defined in zephyr/boards/espressif/esp32s3_devkitc/esp32s3_devkitc-pinctrl.dtsi:96 */
			group2 {
				pinmux = < 0x227fe7 >; /* in zephyr/boards/espressif/esp32s3_devkitc/esp32s3_devkitc-pinctrl.dtsi:97 */
				output-low;            /* in zephyr/boards/espressif/esp32s3_devkitc/esp32s3_devkitc-pinctrl.dtsi:98 */
			};
		};

		/* node '/pin-controller/twai_default' defined in zephyr/boards/espressif/esp32s3_devkitc/esp32s3_devkitc-pinctrl.dtsi:102 */
		twai_default: twai_default {
			phandle = < 0xe >; /* in zephyr/boards/espressif/esp32s3_devkitc/esp32s3_devkitc_procpu.dts:118 */

			/* node '/pin-controller/twai_default/group1' defined in zephyr/boards/espressif/esp32s3_devkitc/esp32s3_devkitc-pinctrl.dtsi:103 */
			group1 {
				pinmux = < 0x3a7fc5 >,
				         < 0xff9d06 >; /* in zephyr/boards/espressif/esp32s3_devkitc/esp32s3_devkitc-pinctrl.dtsi:104 */
			};
		};
	};

	/* node '/clock' defined in zephyr/dts/xtensa/espressif/esp32s3/esp32s3_common.dtsi:82 */
	clock: clock {
		compatible = "espressif,esp32-clock"; /* in zephyr/dts/xtensa/espressif/esp32s3/esp32s3_common.dtsi:83 */
		fast-clk-src = < 0x1 >;               /* in zephyr/dts/xtensa/espressif/esp32s3/esp32s3_common.dtsi:84 */
		slow-clk-src = < 0x0 >;               /* in zephyr/dts/xtensa/espressif/esp32s3/esp32s3_common.dtsi:85 */
		#clock-cells = < 0x1 >;               /* in zephyr/dts/xtensa/espressif/esp32s3/esp32s3_common.dtsi:86 */
		status = "okay";                      /* in zephyr/dts/xtensa/espressif/esp32s3/esp32s3_common.dtsi:87 */
		phandle = < 0x3 >;                    /* in zephyr/dts/xtensa/espressif/esp32s3/esp32s3_common.dtsi:176 */
	};

	/* node '/buttons' defined in zephyr/boards/espressif/esp32s3_devkitc/esp32s3_devkitc_procpu.dts:37 */
	buttons {
		compatible = "gpio-keys"; /* in zephyr/boards/espressif/esp32s3_devkitc/esp32s3_devkitc_procpu.dts:38 */

		/* node '/buttons/button_0' defined in zephyr/boards/espressif/esp32s3_devkitc/esp32s3_devkitc_procpu.dts:40 */
		button0: button_0 {
			gpios = < &gpio0 0x0 0x11 >; /* in zephyr/boards/espressif/esp32s3_devkitc/esp32s3_devkitc_procpu.dts:41 */
			label = "BOOT Button";       /* in zephyr/boards/espressif/esp32s3_devkitc/esp32s3_devkitc_procpu.dts:42 */
			zephyr,code = < 0xb >;       /* in zephyr/boards/espressif/esp32s3_devkitc/esp32s3_devkitc_procpu.dts:43 */
		};
	};

	/* node '/leds' defined in ../Documents/Repos/ZPLC/firmware/app/boards/esp32s3_devkitc_esp32s3_procpu.overlay:31 */
	leds {
		compatible = "gpio-leds"; /* in ../Documents/Repos/ZPLC/firmware/app/boards/esp32s3_devkitc_esp32s3_procpu.overlay:32 */

		/* node '/leds/led_0' defined in ../Documents/Repos/ZPLC/firmware/app/boards/esp32s3_devkitc_esp32s3_procpu.overlay:35 */
		led0: led_0 {
			gpios = < &gpio1 0x6 0x0 >; /* in ../Documents/Repos/ZPLC/firmware/app/boards/esp32s3_devkitc_esp32s3_procpu.overlay:36 */
			label = "ZPLC Output 0";    /* in ../Documents/Repos/ZPLC/firmware/app/boards/esp32s3_devkitc_esp32s3_procpu.overlay:37 */
		};
	};
};
